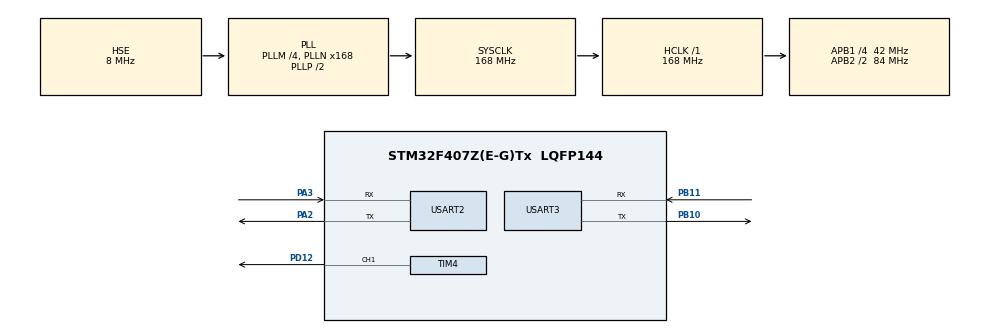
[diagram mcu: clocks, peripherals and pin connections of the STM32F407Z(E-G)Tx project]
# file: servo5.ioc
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Mcu.Family=STM32F4
Mcu.Name=STM32F407Z(E-G)Tx
Mcu.Package=LQFP144
NVIC.PriorityGroup=NVIC_PRIORITYGROUP_4
NVIC.USART2_IRQn=true\:1\:0\:true\:false\:true\:true\:true
NVIC.USART3_IRQn=true\:1\:0\:true\:false\:true\:true\:true
PA13.Mode=JTAG_4_pins
PA13.Signal=SYS_JTMS-SWDIO
PA14.Mode=JTAG_4_pins
PA14.Signal=SYS_JTCK-SWCLK
PA15.Mode=JTAG_4_pins
PA15.Signal=SYS_JTDI
PA2.Mode=Asynchronous
PA2.Signal=USART2_TX
PA3.Mode=Asynchronous
PA3.Signal=USART2_RX
PB10.Mode=Asynchronous
PB10.Signal=USART3_TX
PB11.Mode=Asynchronous
PB11.Signal=USART3_RX
PB3.Mode=JTAG_4_pins
PB3.Signal=SYS_JTDO-SWO
PD12.Signal=S_TIM4_CH1
PH0-OSC_IN.Mode=HSE-External-Oscillator
PH0-OSC_IN.Signal=RCC_OSC_IN
PH1-OSC_OUT.Mode=HSE-External-Oscillator
PH1-OSC_OUT.Signal=RCC_OSC_OUT
ProjectManager.HeapSize=0x200
ProjectManager.StackSize=0x400
ProjectManager.TargetToolchain=Makefile
RCC.48MHZClocksFreq_Value=84000000
RCC.AHBFreq_Value=168000000
RCC.APB1CLKDivider=RCC_HCLK_DIV4
RCC.APB1Freq_Value=42000000
RCC.APB1TimFreq_Value=84000000
RCC.APB2CLKDivider=RCC_HCLK_DIV2
RCC.APB2Freq_Value=84000000
RCC.APB2TimFreq_Value=168000000
RCC.CortexFreq_Value=168000000
RCC.HCLKFreq_Value=168000000
RCC.HSE_VALUE=8000000
RCC.HSI_VALUE=16000000
RCC.LSE_VALUE=32768
RCC.PLLM=4
RCC.PLLN=168
RCC.PLLSourceVirtual=RCC_PLLSOURCE_HSE
RCC.SYSCLKFreq_VALUE=168000000
RCC.SYSCLKSource=RCC_SYSCLKSOURCE_PLLCLK
RCC.VCOOutputFreq_Value=336000000
SH.S_TIM4_CH1.0=TIM4_CH1,PWM Generation1 CH1
TIM4.AutoReloadPreload=TIM_AUTORELOAD_PRELOAD_ENABLE
TIM4.Channel-PWM\ Generation1\ CH1=TIM_CHANNEL_1
TIM4.Period=999
TIM4.Prescaler=83
USART2.VirtualMode=VM_ASYNC
USART3.VirtualMode=VM_ASYNC
VP_TIM4_VS_ClockSourceINT.Mode=Internal
board=custom

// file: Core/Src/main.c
#include "main.h"
#include "tim.h"
#include "usart.h"
#include "gpio.h"

void SystemClock_Config(void);

/* USER CODE BEGIN 0 */
extern void loop(void);
/* USER CODE END 0 */

int main(void)
{

  /* MCU Configuration--------------------------------------------------------*/

  /* Reset of all peripherals, Initializes the Flash interface and the Systick. */
  HAL_Init();

  /* Configure the system clock */
  SystemClock_Config();

  /* Initialize all configured peripherals */
  MX_GPIO_Init();
  MX_USART2_UART_Init();
  MX_USART3_UART_Init();
  MX_TIM4_Init();

  /* USER CODE BEGIN 2 */
  	HAL_UART_Receive_IT(&huart3,&pc_rx_buf,1u);
  HAL_TIM_PWM_Start(&htim4,TIM_CHANNEL_1);
  /* USER CODE END 2 */

  /* Infinite loop */
  while (1)
  {

    /* USER CODE BEGIN 3 */
    WritePosEx(1, cmd.rotate, cmd.rotatespeed, 100);//舵机(ID1),以最高速度V=80(50*80步/秒),加速度A=100(100*100步/秒^2),运行至P1=4095
  }
  /* USER CODE END 3 */
}

void SystemClock_Config(void)
{
  RCC_OscInitTypeDef RCC_OscInitStruct = {0};
  RCC_ClkInitTypeDef RCC_ClkInitStruct = {0};

  /** Configure the main internal regulator output voltage
  */
  __HAL_RCC_PWR_CLK_ENABLE();
  __HAL_PWR_VOLTAGESCALING_CONFIG(PWR_REGULATOR_VOLTAGE_SCALE1);
  /** Initializes the RCC Oscillators according to the specified parameters
  * in the RCC_OscInitTypeDef structure.
  */
  RCC_OscInitStruct.OscillatorType = RCC_OSCILLATORTYPE_HSE;
  RCC_OscInitStruct.HSEState = RCC_HSE_ON;
  RCC_OscInitStruct.PLL.PLLState = RCC_PLL_ON;
  RCC_OscInitStruct.PLL.PLLSource = RCC_PLLSOURCE_HSE;
  RCC_OscInitStruct.PLL.PLLM = 4;
  RCC_OscInitStruct.PLL.PLLN = 168;
  RCC_OscInitStruct.PLL.PLLP = RCC_PLLP_DIV2;
  RCC_OscInitStruct.PLL.PLLQ = 4;
  if (HAL_RCC_OscConfig(&RCC_OscInitStruct) != HAL_OK)
  {
    Error_Handler();
  }
  /** Initializes the CPU, AHB and APB buses clocks
  */
  RCC_ClkInitStruct.ClockType = RCC_CLOCKTYPE_HCLK|RCC_CLOCKTYPE_SYSCLK
                              |RCC_CLOCKTYPE_PCLK1|RCC_CLOCKTYPE_PCLK2;
  RCC_ClkInitStruct.SYSCLKSource = RCC_SYSCLKSOURCE_PLLCLK;
  RCC_ClkInitStruct.AHBCLKDivider = RCC_SYSCLK_DIV1;
  RCC_ClkInitStruct.APB1CLKDivider = RCC_HCLK_DIV4;
  RCC_ClkInitStruct.APB2CLKDivider = RCC_HCLK_DIV2;

  if (HAL_RCC_ClockConfig(&RCC_ClkInitStruct, FLASH_LATENCY_5) != HAL_OK)
  {
    Error_Handler();
  }
}

/* USER CODE BEGIN 4 */
void HAL_UART_RxCpltCallback(UART_HandleTypeDef * huart)
{
  if(huart == &huart3)
	{

		  PCData();
        __HAL_TIM_SET_COMPARE(&htim4,TIM_CHANNEL_1,cmd.line);
       HAL_UART_Receive_IT(&huart3,&pc_rx_buf,1);
	}
}

/* USER CODE END 4 */
